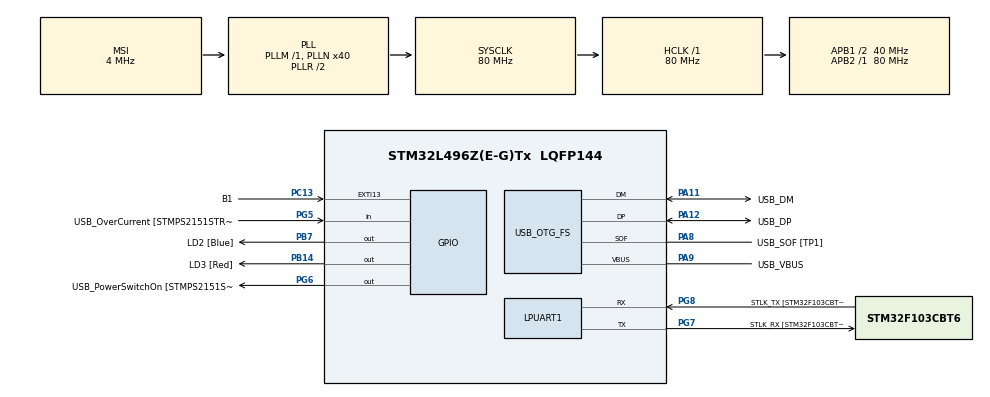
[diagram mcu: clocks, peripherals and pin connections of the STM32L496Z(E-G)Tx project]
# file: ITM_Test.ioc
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Mcu.Family=STM32L4
PG8.Mode=Asynchronous
RCC.CortexFreq_Value=80000000
PG6.Signal=GPIO_Output
PG8.Signal=LPUART1_RX
PB14.GPIO_Label=LD3 [Red]
PG6.GPIO_Label=USB_PowerSwitchOn [STMPS2151STR_EN]
RCC.SYSCLKSourceVirtual=RCC_SYSCLKSOURCE_PLLCLK
PA11.Mode=Device_Only
PC15-OSC32_OUT\ (PC15).Mode=LSE-External-Oscillator
PC13.GPIO_Label=B1
PG5.GPIO_Label=USB_OverCurrent [STMPS2151STR_FAULT]
RCC.SYSCLKSource=RCC_SYSCLKSOURCE_PLLCLK
ProjectManager.StackSize=0x400
PC14-OSC32_IN\ (PC14).Mode=LSE-External-Oscillator
PA14\ (JTCK/SWCLK).Signal=SYS_JTCK-SWCLK
PA12.Signal=USB_OTG_FS_DP
RCC.HCLKFreq_Value=80000000
RCC.APB2TimFreq_Value=80000000
RCC.AHBFreq_Value=80000000
RCC.HSE_VALUE=8000000
RCC.PLLMUL=RCC_PLL_MUL9
PA13\ (JTMS/SWDIO).GPIO_Label=TMS
PA10.GPIO_Label=USB_ID
PB7.Signal=GPIO_Output
PA8.Signal=USB_OTG_FS_SOF
PA14\ (JTCK/SWCLK).Mode=Trace_Asynchronous_SW
PB7.GPIO_Label=LD2 [Blue]
Mcu.Package=LQFP144
PA10.Signal=USB_OTG_FS_ID
USB_OTG_FS.VirtualMode=Device_Only
PA14\ (JTCK/SWCLK).GPIO_Label=TCK
RCC.APB1TimFreq_Value=80000000
RCC.HSI48_VALUE=48000000
RCC.PLLSAI1N=24
PB3\ (JTDO/TRACESWO).GPIO_Label=SWO
RCC.MSI_VALUE=4000000
PG7.Signal=LPUART1_TX
PA13\ (JTMS/SWDIO).Mode=Trace_Asynchronous_SW
PG5.Signal=GPIO_Input
PC13.Signal=GPXTI13
PA9.GPIO_Label=USB_VBUS
PA11.GPIO_Label=USB_DM
PC15-OSC32_OUT\ (PC15).Signal=RCC_OSC32_OUT
RCC.APB1CLKDivider=RCC_HCLK_DIV2
PA12.GPIO_Label=USB_DP
PH1-OSC_OUT\ (PH1).Signal=RCC_OSC_OUT
PG8.GPIO_Label=STLK_TX [STM32F103CBT6_PA2]
PA9.Mode=Activate_VBUS
PA8.GPIO_Label=USB_SOF [TP1]
PB3\ (JTDO/TRACESWO).Signal=SYS_JTDO-SWO
ProjectManager.TargetToolchain=EWARM V8.32
PA9.Signal=USB_OTG_FS_VBUS
RCC.USBFreq_Value=48000000
PG7.Mode=Asynchronous
PB14.Signal=GPIO_Output
board=NUCLEO-L496ZG
RCC.VCOOutputFreq_Value=160000000
RCC.APB2Freq_Value=80000000
RCC.PRESCALERUSB=RCC_USBCLKSOURCE_PLL_DIV1_5
PG7.GPIO_Label=STLK_RX [STM32F103CBT6_PA3]
RCC.ADCFreq_Value=48000000
Mcu.Name=STM32L496Z(E-G)Tx
RCC.48MHZClocksFreq_Value=24000000
RCC.SYSCLKFreq_VALUE=80000000
PA12.Mode=Device_Only
PC14-OSC32_IN\ (PC14).Signal=RCC_OSC32_IN
PA11.Signal=USB_OTG_FS_DM
ProjectManager.HeapSize=0x200
RCC.HSI_VALUE=16000000
NVIC.PriorityGroup=NVIC_PRIORITYGROUP_4
PB3\ (JTDO/TRACESWO).Mode=Trace_Asynchronous_SW
RCC.PLLN=40
PA8.Mode=Activate_SOF_FS
RCC.APB1Freq_Value=40000000
PA13\ (JTMS/SWDIO).Signal=SYS_JTMS-SWDIO

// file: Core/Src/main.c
/* USER CODE BEGIN Header */
/**
  ******************************************************************************
  * @file           : main.c
  * @brief          : Main program body
  ******************************************************************************
  * @attention
  *
  * <h2><center>&copy; Copyright (c) 2020 STMicroelectronics.
  * All rights reserved.</center></h2>
  *
  * This software component is licensed by ST under BSD 3-Clause license,
  * the "License"; You may not use this file except in compliance with the
  * License. You may obtain a copy of the License at:
  *                        opensource.org/licenses/BSD-3-Clause
  *
  ******************************************************************************
  */
/* USER CODE END Header */
#include "main.h"
#include "usart.h"
#include "usb_otg.h"
#include "gpio.h"

/* USER CODE BEGIN Includes */
#include <arm_itm.h>
/* USER CODE END Includes */

/* USER CODE BEGIN PV */
uint32_t flag;
uint32_t i;
/* USER CODE END PV */

void SystemClock_Config(void);

int main(void)
{

  /* MCU Configuration--------------------------------------------------------*/

  /* Reset of all peripherals, Initializes the Flash interface and the Systick. */
  HAL_Init();

  /* Configure the system clock */
  SystemClock_Config();

  /* Initialize all configured peripherals */
  MX_GPIO_Init();
  MX_LPUART1_UART_Init();
  MX_USB_OTG_FS_PCD_Init();
  /* USER CODE BEGIN 2 */
  HAL_SYSTICK_Config(HAL_RCC_GetHCLKFreq()/10);
  /* USER CODE END 2 */

  /* Infinite loop */
  while (1)
  {
    if(flag == 1){
      flag = 0;
      i++;
      ITM_EVENT32_WITH_PC(1,i);
    }
  }
}

void SystemClock_Config(void)
{
  RCC_OscInitTypeDef RCC_OscInitStruct = {0};
  RCC_ClkInitTypeDef RCC_ClkInitStruct = {0};
  RCC_PeriphCLKInitTypeDef PeriphClkInit = {0};

  /** Configure LSE Drive Capability
  */
  HAL_PWR_EnableBkUpAccess();
  __HAL_RCC_LSEDRIVE_CONFIG(RCC_LSEDRIVE_LOW);
  /** Initializes the RCC Oscillators according to the specified parameters
  * in the RCC_OscInitTypeDef structure.
  */
  RCC_OscInitStruct.OscillatorType = RCC_OSCILLATORTYPE_LSE|RCC_OSCILLATORTYPE_MSI;
  RCC_OscInitStruct.LSEState = RCC_LSE_ON;
  RCC_OscInitStruct.MSIState = RCC_MSI_ON;
  RCC_OscInitStruct.MSICalibrationValue = 0;
  RCC_OscInitStruct.MSIClockRange = RCC_MSIRANGE_6;
  RCC_OscInitStruct.PLL.PLLState = RCC_PLL_ON;
  RCC_OscInitStruct.PLL.PLLSource = RCC_PLLSOURCE_MSI;
  RCC_OscInitStruct.PLL.PLLM = 1;
  RCC_OscInitStruct.PLL.PLLN = 40;
  RCC_OscInitStruct.PLL.PLLP = RCC_PLLP_DIV2;
  RCC_OscInitStruct.PLL.PLLQ = RCC_PLLQ_DIV2;
  RCC_OscInitStruct.PLL.PLLR = RCC_PLLR_DIV2;
  if (HAL_RCC_OscConfig(&RCC_OscInitStruct) != HAL_OK)
  {
    Error_Handler();
  }
  /** Initializes the CPU, AHB and APB buses clocks
  */
  RCC_ClkInitStruct.ClockType = RCC_CLOCKTYPE_HCLK|RCC_CLOCKTYPE_SYSCLK
                              |RCC_CLOCKTYPE_PCLK1|RCC_CLOCKTYPE_PCLK2;
  RCC_ClkInitStruct.SYSCLKSource = RCC_SYSCLKSOURCE_PLLCLK;
  RCC_ClkInitStruct.AHBCLKDivider = RCC_SYSCLK_DIV1;
  RCC_ClkInitStruct.APB1CLKDivider = RCC_HCLK_DIV2;
  RCC_ClkInitStruct.APB2CLKDivider = RCC_HCLK_DIV1;

  if (HAL_RCC_ClockConfig(&RCC_ClkInitStruct, FLASH_LATENCY_4) != HAL_OK)
  {
    Error_Handler();
  }
  PeriphClkInit.PeriphClockSelection = RCC_PERIPHCLK_LPUART1|RCC_PERIPHCLK_USB;
  PeriphClkInit.Lpuart1ClockSelection = RCC_LPUART1CLKSOURCE_PCLK1;
  PeriphClkInit.UsbClockSelection = RCC_USBCLKSOURCE_PLLSAI1;
  PeriphClkInit.PLLSAI1.PLLSAI1Source = RCC_PLLSOURCE_MSI;
  PeriphClkInit.PLLSAI1.PLLSAI1M = 1;
  PeriphClkInit.PLLSAI1.PLLSAI1N = 24;
  PeriphClkInit.PLLSAI1.PLLSAI1P = RCC_PLLP_DIV2;
  PeriphClkInit.PLLSAI1.PLLSAI1Q = RCC_PLLQ_DIV2;
  PeriphClkInit.PLLSAI1.PLLSAI1R = RCC_PLLR_DIV2;
  PeriphClkInit.PLLSAI1.PLLSAI1ClockOut = RCC_PLLSAI1_48M2CLK;
  if (HAL_RCCEx_PeriphCLKConfig(&PeriphClkInit) != HAL_OK)
  {
    Error_Handler();
  }
  /** Configure the main internal regulator output voltage
  */
  if (HAL_PWREx_ControlVoltageScaling(PWR_REGULATOR_VOLTAGE_SCALE1) != HAL_OK)
  {
    Error_Handler();
  }
  /** Enable MSI Auto calibration
  */
  HAL_RCCEx_EnableMSIPLLMode();
}

/* USER CODE BEGIN 4 */
void ITM_Test()
{
  flag = 1;
}
/* USER CODE END 4 */

void Error_Handler(void)
{
}

/************************ (C) COPYRIGHT STMicroelectronics *****END OF FILE****/
